# Polarfire SoC register map
Vendor: Microchip; File version: 1.0
CPU: Microchip PolarFire SoC 1.0, little endian
Registers are 32-bit, read-write, reset 0x0 unless marked. A register's access mark holds for its fields unless they carry their own. Offsets are from the block's base; [hi:lo] are bit positions; {n}, {i} and the like mark numbered series.

## IOSCB_MUX_MSS — IOSCB MSS Clock Management Controller
Base 0x3E002000
0x00 SOFT_RESET
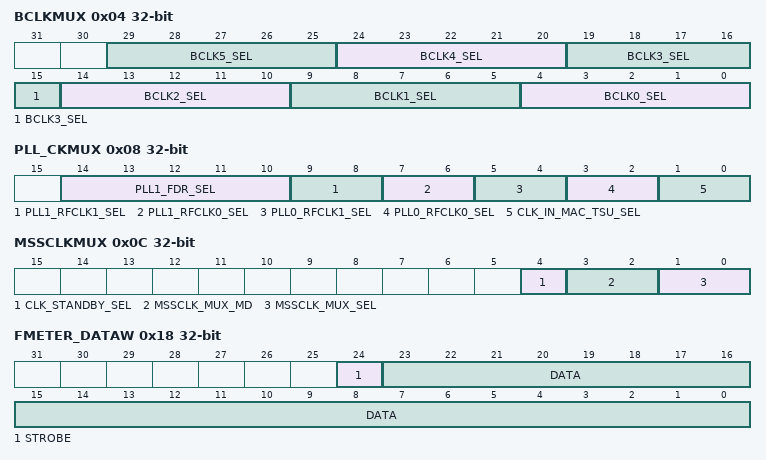
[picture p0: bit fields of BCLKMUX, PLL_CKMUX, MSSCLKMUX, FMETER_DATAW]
0x04 BCLKMUX — Bus clock multiplexer register
  [5n+4:5n] BCLK{n}_SEL (n=0..5)
0x08 PLL_CKMUX — PLL clock multiplexer register
  [14:10] PLL1_FDR_SEL, [9:8] PLL1_RFCLK1_SEL, [7:6] PLL1_RFCLK0_SEL, [5:4] PLL0_RFCLK1_SEL, [3:2] PLL0_RFCLK0_SEL, [1:0] CLK_IN_MAC_TSU_SEL
0x0C MSSCLKMUX — MSS clock multiplexer register
  [4] CLK_STANDBY_SEL, [3:2] MSSCLK_MUX_MD, [1:0] MSSCLK_MUX_SEL
0x10 SPARE0 — Spare register 0
0x14 FMETER_ADDR — Frequency meter address register
  [5:2] ADDR
0x18 FMETER_DATAW — Frequency meter data write register
  [24] STROBE wo, [23:0] DATA
0x1C FMETER_DATAR — Frequency meter data read register
  [23:0] DATA ro
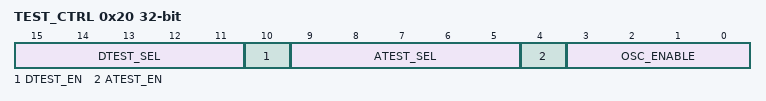
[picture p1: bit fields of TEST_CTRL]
0x20 TEST_CTRL — Test control register
  [15:11] DTEST_SEL, [10] DTEST_EN, [9:5] ATEST_SEL, [4] ATEST_EN, [3:0] OSC_ENABLE

## IOSCB_IO_CALIB_DDR — IOSCB DDR IO Calibration Controller
Base 0x3E040000
Same registers: IOSCB_IO_CALIB_SGMII 0x3E800000
0x00 SOFT_RESET_IOCALIB — Soft reset IO calibration register
0x04 IOC_REG0 — IO calibration register 0
{0x4+4i} IOC_REG{i} ro (i=1..5) — IO calibration register {i}
0x1C IOC_REG6 — IO calibration register 6

## IOSCB_MUX_SGMII — IOSCB SGMII Clock Management Controller
Base 0x3E200000
0x00 SOFT_RESET
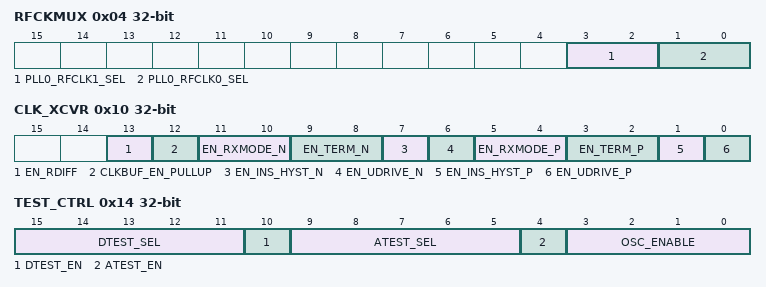
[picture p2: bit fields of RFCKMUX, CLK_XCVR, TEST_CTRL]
0x04 RFCKMUX — RF clock multiplexer register
  [3:2] PLL0_RFCLK1_SEL, [1:0] PLL0_RFCLK0_SEL
0x08 SGMII_CLKMUX — SGMII clock multiplexer register
0x0C SPARE0 — Spare register 0
0x10 CLK_XCVR — Clock transceiver register
  [13] EN_RDIFF, [12] CLKBUF_EN_PULLUP, [11:10] EN_RXMODE_N, [9:8] EN_TERM_N, [7] EN_INS_HYST_N, [6] EN_UDRIVE_N, [5:4] EN_RXMODE_P, [3:2] EN_TERM_P, [1] EN_INS_HYST_P, [0] EN_UDRIVE_P
0x14 TEST_CTRL — Test control register
  [15:11] DTEST_SEL, [10] DTEST_EN, [9:5] ATEST_SEL, [4] ATEST_EN, [3:0] OSC_ENABLE

## ENVM — ENVM Controller
Base 0x20200000
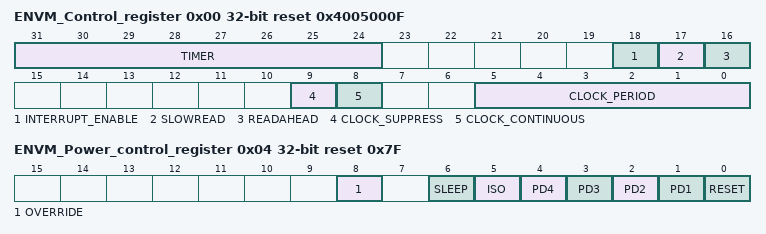
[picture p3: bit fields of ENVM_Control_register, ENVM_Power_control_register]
0x00 ENVM_Control_register reset 0x4005000F
  [31:24] TIMER — Sets the duration of the timer used to detect a non-response of slow response from the ENVM on C and R bus accesses. Timer Duration = (Value+1) * (128 * AHB Clock Period) 0x00: Timer disabled. If the timer expires the AHB cycle is terminates using the HRESP protocol. The time should be set.
  [18] INTERRUPT_ENABLE — Enable the ENVM interrupt
  [17] SLOWREAD — When '1' the controller will initiate separate ENVM reads for all reads. No buffering or speculative operations will be carried out. When performing word reads incrementing through ENVM each location will be read twice
  [16] READAHEAD — Enables "readahead" on the ENVM controller. The controller will automatically read the next ENVM location as soon as possible ahead of the AHB request. This will improve read performance when incrementing though memory as the NVM reads and AHB cycles are pipelined. When set non incrementing accesses will take longer as the controller may be in the process of reading the next address and the ENVM cycle needs to complete prior to starting the required read
  [9] CLOCK_SUPPRESS — When set suppresses clock edge between C-Bus access cycles so that they appear as consecutive access cycles.
  [8] CLOCK_CONTINUOUS — When '1' the ENVM clock will be always generated, and not stopped between access cycles. Setting this will increase access latency but mean that the ENVM clock operates at a stable rate.
  [5:0] CLOCK_PERIOD — Sets the number of AHB cycles used to generate the ENVM clock, Clock period = (Value+1) * 2.5ns (AHB clock at 400MHz). Value must be 1 to 63 (0 defaults to 15) e.g.15 will generate a 40ns period if the AHB clock is 400MHz
0x04 ENVM_Power_control_register reset 0x7F
  [8] OVERRIDE — Use the ENVM_CR here rather than the SYSREG one
  [6] SLEEP
  [5] ISO — iso (isolate)
  [n] PD{n} (n=1..4) — pd{n} (powerdown)
  [0] RESET
